# CY8C5888LTI_LP097 register map
File version: 0.1
CY8C58LP
Registers are 8-bit, read-write, no defined reset value unless marked. A register's access mark holds for its fields unless they carry their own. Offsets are from the block's base; lines under a group give offsets from that group; [hi:lo] are bit positions; {n}, {i} and the like mark numbered series; 'fields as' and 'values as' point back to an identical list; <NAME> marks a mode.

## Memory map
0x00000000 ADC_1 — SAR ADC
0x00000000 UART
0x00000000 ADC_2 — SAR ADC

## ADC_1 — SAR ADC
Base 0x00000000
0x40004614 SAR_TR0 — SAR trim register
{0x40005900+i} SAR_CSR{i} (i=0..6) — SAR status and control register {i}
0x40005B20 SAR_SW0 — SAR Analog Routing Register 0
{0x40005B20+i} SAR_SW{i} (i=2..4) — SAR Analog Routing Register {i}
0x40005B26 SAR_SW6 — SAR Analog Routing Register 6
0x40005B27 SAR_CLK — SAR Clock Selection Register
0x40005BA0 SAR_WRK 16-bit — SAR working register

## UART
Base 0x00000000
0x4000654B TX_UART_TX_DATA — TX Data Register
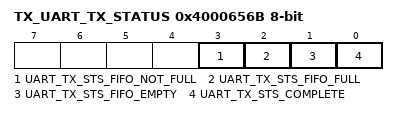
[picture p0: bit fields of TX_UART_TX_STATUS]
0x4000656B TX_UART_TX_STATUS — TX status register
  [3] UART_TX_STS_FIFO_NOT_FULL ro, [2] UART_TX_STS_FIFO_FULL ro, [1] UART_TX_STS_FIFO_EMPTY ro, [0] UART_TX_STS_COMPLETE ro

## ADC_2 — SAR ADC
Base 0x00000000
0x40004616 SAR_TR0 — SAR trim register
{0x40005908+i} SAR_CSR{i} (i=0..6) — SAR status and control register {i}
0x40005B28 SAR_SW0 — SAR Analog Routing Register 0
{0x40005B28+i} SAR_SW{i} (i=2..4) — SAR Analog Routing Register {i}
0x40005B2E SAR_SW6 — SAR Analog Routing Register 6
0x40005B2F SAR_CLK — SAR Clock Selection Register
0x40005BA2 SAR_WRK 16-bit — SAR working register
